# STM32L4R5 register map
File version: 2.4
CPU: CM4 r0p1, little endian, MPU, FPU, 4 interrupt priority bits
Registers are 32-bit, read-write, reset 0x0 unless marked. A register's access mark holds for its fields unless they carry their own. Offsets are from the block's base; [hi:lo] are bit positions; {n}, {i} and the like mark numbered series; 'fields as' and 'values as' point back to an identical list.

## HASH — Hash processor
Base 0x50060400
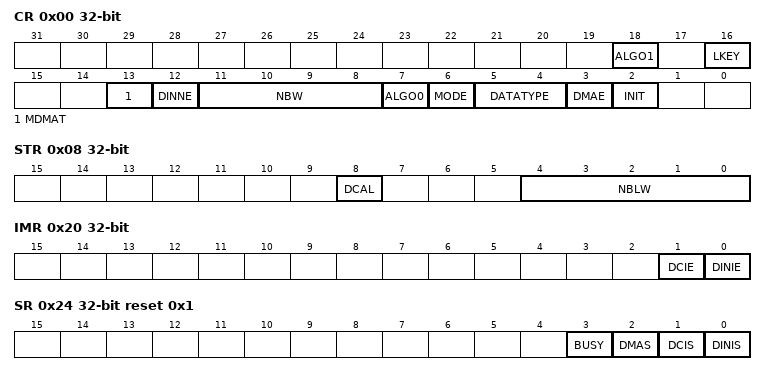
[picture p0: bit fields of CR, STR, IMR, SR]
0x00 CR access per field — control register
  [18] ALGO1 rw — ALGO
  [16] LKEY rw — Long key selection
  [13] MDMAT rw — Multiple DMA Transfers
  [12] DINNE ro — DIN not empty
  [11:8] NBW ro — Number of words already pushed
  [7] ALGO0 rw — Algorithm selection
  [6] MODE rw — Mode selection
  [5:4] DATATYPE rw — Data type selection
  [3] DMAE rw — DMA enable
  [2] INIT wo — Initialize message digest calculation
0x04 DIN — data input register
  [31:0] DATAIN — Data input
0x08 STR access per field — start register
  [8] DCAL wo — Digest calculation
  [4:0] NBLW rw — Number of valid bits in the last word of the message
0x0C HR0 ro — digest registers
  [31:0] H0
0x20 IMR — interrupt enable register
  [1] DCIE — Digest calculation completion interrupt enable
  [0] DINIE — Data input interrupt enable
0x24 SR access per field reset 0x1 — status register
  [3] BUSY ro — Busy bit
  [2] DMAS ro — DMA Status
  [1] DCIS rw — Digest calculation completion interrupt status
  [0] DINIS rw — Data input interrupt status
{0xF8+4i} CSR{i} (i=0..53) — context swap registers
0x310 HASH_HR0 ro — HASH digest register
  [31:0] H0
{0x310+4i} HASH_HR{i} ro (i=1..7) — read-only
  [31:0] H{i}

## DMA2D — DMA2D controller
Base 0x4002B000
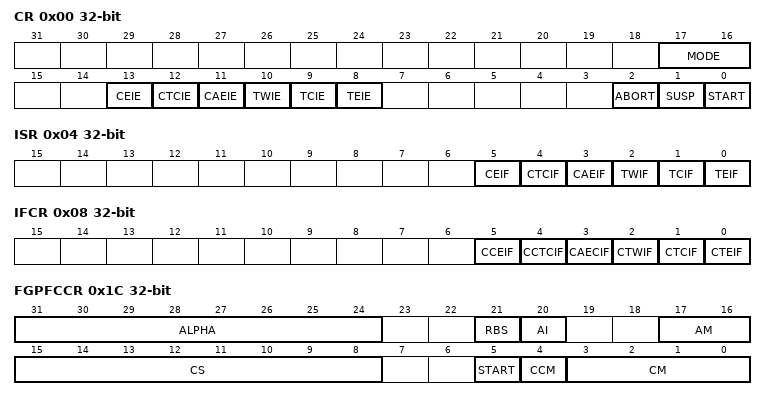
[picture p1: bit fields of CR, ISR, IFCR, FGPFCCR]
0x00 CR — control register
  [17:16] MODE — DMA2D mode
  [13] CEIE — Configuration Error Interrupt Enable
  [12] CTCIE — CLUT transfer complete interrupt enable
  [11] CAEIE — CLUT access error interrupt enable
  [10] TWIE — Transfer watermark interrupt enable
  [9] TCIE — Transfer complete interrupt enable
  [8] TEIE — Transfer error interrupt enable
  [2] ABORT
  [1] SUSP — Suspend
  [0] START
0x04 ISR ro — Interrupt Status Register
  [5] CEIF — Configuration error interrupt flag
  [4] CTCIF — CLUT transfer complete interrupt flag
  [3] CAEIF — CLUT access error interrupt flag
  [2] TWIF — Transfer watermark interrupt flag
  [1] TCIF — Transfer complete interrupt flag
  [0] TEIF — Transfer error interrupt flag
0x08 IFCR — interrupt flag clear register
  [5] CCEIF — Clear configuration error interrupt flag
  [4] CCTCIF — Clear CLUT transfer complete interrupt flag
  [3] CAECIF — Clear CLUT access error interrupt flag
  [2] CTWIF — Clear transfer watermark interrupt flag
  [1] CTCIF — Clear transfer complete interrupt flag
  [0] CTEIF — Clear Transfer error interrupt flag
0x0C FGMAR — foreground memory address register
  [31:0] MA — Memory address
0x10 FGOR — foreground offset register
  [13:0] LO — Line offset
0x14 BGMAR — background memory address register
  [31:0] MA — Memory address
0x18 BGOR — background offset register
  [13:0] LO — Line offset
0x1C FGPFCCR — foreground PFC control register
  [31:24] ALPHA — Alpha value
  [21] RBS — Red Blue Swap
  [20] AI — Alpha Inverted
  [17:16] AM — Alpha mode
  [15:8] CS — CLUT size
  [5] START
  [4] CCM — CLUT color mode
  [3:0] CM — Color mode
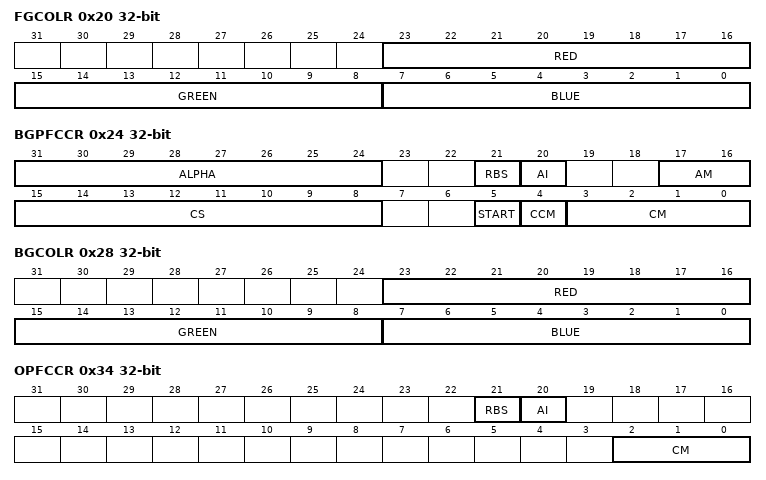
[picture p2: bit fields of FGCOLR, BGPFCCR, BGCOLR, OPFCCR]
0x20 FGCOLR — foreground color register
  [23:16] RED — Red Value
  [15:8] GREEN — Green Value
  [7:0] BLUE — Blue Value
0x24 BGPFCCR — background PFC control register
  [31:24] ALPHA — Alpha value
  [21] RBS — Red Blue Swap
  [20] AI — Alpha Inverted
  [17:16] AM — Alpha mode
  [15:8] CS — CLUT size
  [5] START
  [4] CCM — CLUT Color mode
  [3:0] CM — Color mode
0x28 BGCOLR — background color register
  fields as FGCOLR
0x2C FGCMAR — foreground CLUT memory address register
  [31:0] MA — Memory Address
0x30 BGCMAR — background CLUT memory address register
  [31:0] MA — Memory address
0x34 OPFCCR — output PFC control register
  [21] RBS — Red Blue Swap
  [20] AI — Alpha Inverted
  [2:0] CM — Color mode
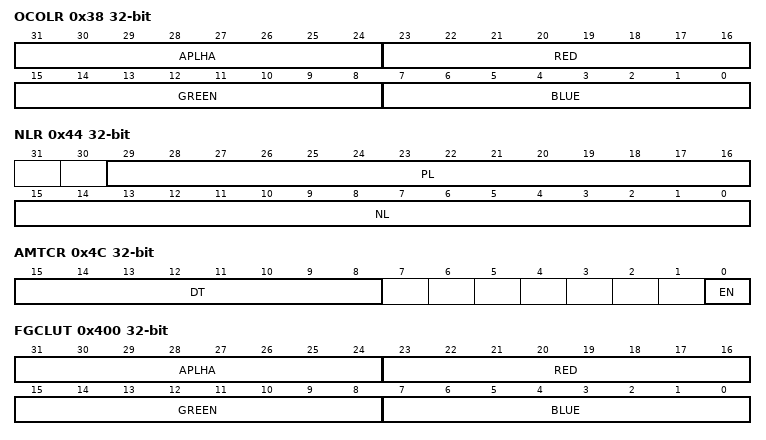
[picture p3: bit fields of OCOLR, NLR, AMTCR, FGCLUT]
0x38 OCOLR — output color register
  [31:24] APLHA — Alpha Channel Value
  [23:16] RED — Red Value
  [15:8] GREEN — Green Value
  [7:0] BLUE — Blue Value
0x3C OMAR — output memory address register
  [31:0] MA — Memory Address
0x40 OOR — output offset register
  [13:0] LO — Line Offset
0x44 NLR — number of line register
  [29:16] PL — Pixel per lines
  [15:0] NL — Number of lines
0x48 LWR — line watermark register
  [15:0] LW — Line watermark
0x4C AMTCR — AHB master timer configuration register
  [15:8] DT — Dead Time
  [0] EN — Enable
0x400 FGCLUT
  [31:24] APLHA, [23:16] RED, [15:8] GREEN, [7:0] BLUE
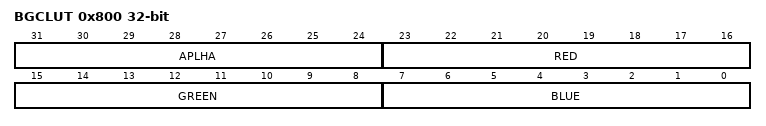
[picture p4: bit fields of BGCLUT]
0x800 BGCLUT
  [31:24] APLHA, [23:16] RED, [15:8] GREEN, [7:0] BLUE

## GFXMMU — Graphic MMU
Base 0x4002C000
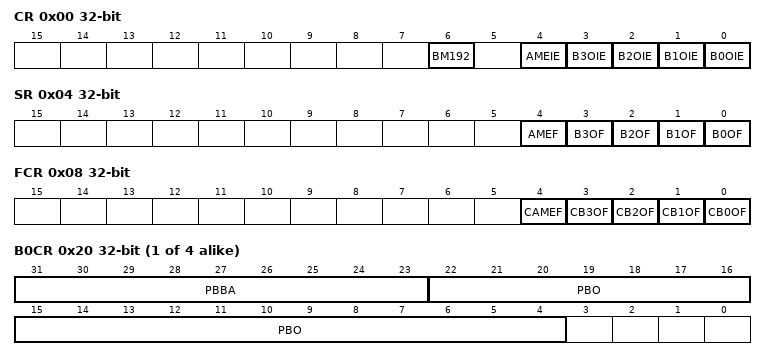
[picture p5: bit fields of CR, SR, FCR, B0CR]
0x00 CR — Graphic MMU configuration register
  [6] BM192 — 192 Block mode
  [4] AMEIE — AHB master error interrupt enable
  [n] B{n}OIE (n=0..3) — Buffer {n} overflow interrupt enable
0x04 SR ro — Graphic MMU status register
  [4] AMEF — AHB master error flag
  [n] B{n}OF (n=0..3) — Buffer {n} overflow flag
0x08 FCR wo — Graphic MMU flag clear register
  [4] CAMEF — Clear AHB master error flag
  [n] CB{n}OF (n=0..3) — Clear buffer {n} overflow flag
0x10 DVR — Graphic MMU default value register
  [31:0] DV — Default value
{0x20+4i} B{i}CR (i=0..3) — Graphic MMU buffer {i} configuration register
  [31:23] PBBA — Physical buffer base address
  [22:4] PBO — Physical buffer offset
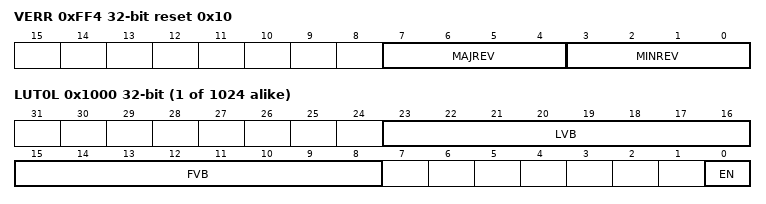
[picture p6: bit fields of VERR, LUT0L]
0xFF4 VERR ro reset 0x10 — Graphic MMU version register
  [7:4] MAJREV — Major revision
  [3:0] MINREV — Minor revision
0xFF8 IPIDR ro reset 0x160061 — Graphic MMU identification register
  [31:0] ID — Identification Code
0xFFC SIDR ro reset 0xA3C5DD04 — Graphic MMU size identification register
  [31:0] SID — Size and ID
{0x1000+8i} LUT{i}L (i=0..1023) — Graphic MMU LUT entry {i} low
  [23:16] LVB — Last Valid Block
  [15:8] FVB — First Valid Block
  [0] EN — Enable
{0x1004+8i} LUT{i}H (i=0..1023) — Graphic MMU LUT entry {i} high
  [21:4] LO — Line offset

## OCTOSPIM — OctoSPI IO Manager
Base 0x50061C00
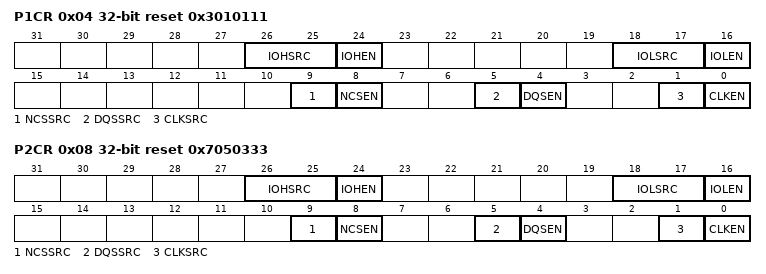
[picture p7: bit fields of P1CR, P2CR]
0x04 P1CR reset 0x3010111 — OctoSPI IO Manager Port 1 Configuration Register
  [26:25] IOHSRC — Source for Port
  [24] IOHEN — Enable for Port n
  [18:17] IOLSRC — Source for Port
  [16] IOLEN — Enable for Port
  [9] NCSSRC — CS Source for Port
  [8] NCSEN — CS Enable for Port
  [5] DQSSRC — DQS Source for Port
  [4] DQSEN — DQS Enable for Port
  [1] CLKSRC — CLK/CLK Source for Port
  [0] CLKEN — CLK/CLK Enable for Port
0x08 P2CR reset 0x7050333 — OctoSPI IO Manager Port 2 Configuration Register
  fields as P1CR
